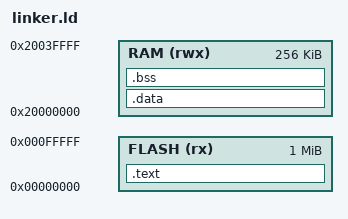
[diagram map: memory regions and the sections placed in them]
/* Minimal linker script for ARM Cortex-M4F (nRF52840) */
MEMORY
{
    FLASH (rx)  : ORIGIN = 0x00000000, LENGTH = 1024K
    RAM   (rwx) : ORIGIN = 0x20000000, LENGTH = 256K
}

ENTRY(Reset_Handler)

SECTIONS
{
    .text :
    {
        KEEP(*(.isr_vector))
        *(.text*)
        *(.rodata*)
        . = ALIGN(4);
        _etext = .;
    } > FLASH

    .data : AT(_etext)
    {
        _sdata = .;
        *(.data*)
        . = ALIGN(4);
        _edata = .;
    } > RAM

    .bss :
    {
        _sbss = .;
        *(.bss*)
        *(COMMON)
        . = ALIGN(4);
        _ebss = .;
    } > RAM

    _estack = ORIGIN(RAM) + LENGTH(RAM);
}

/* Default handler */
PROVIDE(Reset_Handler = main);
